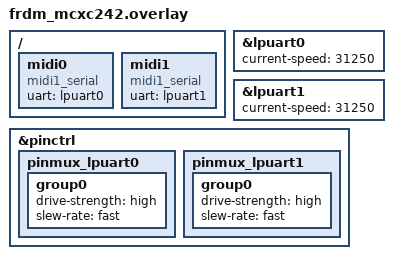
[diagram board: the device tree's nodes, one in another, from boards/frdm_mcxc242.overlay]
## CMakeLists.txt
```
# SPDX-License-Identifier: Apache-2.0

# @file CMakeLists.txt for MIDI1.0 driver app 
#
# @author Jan-Willem Smaal <usenet@gispen.org> 
# @date 20260119
cmake_minimum_required(VERSION 3.20.0)
find_package(Zephyr REQUIRED HINTS $ENV{ZEPHYR_BASE})
project(midi1_serial)

# Application logic 
FILE(GLOB app_sources src/*.c)


target_include_directories(app PRIVATE)

target_sources(app PRIVATE 
	src/main.c
)
```

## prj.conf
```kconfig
# SPDX-License-Identifier: Apache-2.0

##########################################################################
# @file prj.conf
# @brief Example MIDI1.0 Zepyr application
# @note
#
# @author Jan-Willem Smaal <usenet@gispen.org
# @date 20251220
##########################################################################
CONFIG_LOG=n
CONFIG_LOG_DEFAULT_LEVEL=0

# Let's disable the boot banner because
# on the FRDM_MCXC242 overlay we use it will go out 
# the MIDI1.0 DIN port...
CONFIG_BOOT_BANNER=y

CONFIG_MIDI1_SERIAL=y
CONFIG_MIDI1_HARMONIC=y

##########################################################################
# Tune these settings to reduce the RAM footprint
##########################################################################
CONFIG_IDLE_STACK_SIZE=128
CONFIG_ISR_STACK_SIZE=1024

# EOF
```

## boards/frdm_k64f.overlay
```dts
/*
 * SPDX-License-Identifier: Apache-2.0
 */

/**
 * @file frdm_k64f.overlay
 * @brief overlay for this (older) NXP board
 * @note
 * it is using a MIDI arduino shield but I disconnected
 * the 5V and connected it to 3.3V instead to protect the MCU inputs.
 * I should lower the output and input from 220R resistors to 33R but it
 * seems to "work" on some interfaces without that in some shape or form.
 *
 * @author Jan-Willem Smaal <usenet@gispen.org>
 * @date 20260102
 */

/*
 * Classic MIDI1.0 over DIN5 plug
 */
&uart3 {
	status = "okay";
	/* Set it to the MIDI baud rate */
	current-speed = <31250>;
};


/ {
	midi0: midi0 {
                status = "okay";
                compatible = "midi1_serial";
                uart = <&uart3>;
        };
};


/* EOF */
```

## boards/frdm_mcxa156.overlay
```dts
/*
 * SPDX-License-Identifier: Apache-2.0
 */

/**
 * @file frdm_k64f.overlay
 * @brief overlay for this board from 2024
 * @note
 *
 * Using the MCXA156 the mikroBUS socket is used for lpuart1.
 *
 * @author Jan-Willem Smaal <usenet@gispen.org>
 * @date 20260102
 */

/*
 * Classic MIDI1.0 over DIN5 plug.
 * On the MCXA156 the mikroBUS socket J1 is on LPUART1
 */
&lpuart1 {
	status = "okay";
	/* Set it to the MIDI baud rate */
	current-speed = <31250>;
};

/ {
	midi0: midi0 {
                status = "okay";
                compatible = "midi1_serial";
                uart = <&lpuart1>;
        };	
};
```

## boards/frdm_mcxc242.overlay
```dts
/*
 * SPDX-License-Identifier: Apache-2.0
 */

/*
 * @brief FRDM-MCXW242 board configuration for the MIDI1.0 demo 
 * @note
 *
 * @author Jan-Willem Smaal
 * @date 20250101
 */
 
/*
 * Classic MIDI1.0 over DIN5 plug.
 * note on the FRDM-MCXC242 the LPUART0 is shared with the MCU_LINK.
 * so be aware!   If you send printk's you need to set the baud rate
 * to 31250 from the default 115200 to see something usefull
 *
 * Also note anything you send out to the MCU_LINK will end up on the MIDI
 * port!
 *
 */
&lpuart0 {
	status = "okay";
	/* Set it to the MIDI baud rate */
	current-speed = <31250>;
};

/* This one is on the MIKRObus and is not shared with the MCU_LINK. */
&lpuart1 {
	status = "okay";
	/* Set it to the MIDI baud rate */
	current-speed = <31250>;
};

&pinctrl {
	pinmux_lpuart0: pinmux_lpuart0 {
		group0 {
			/* Strongest drive + fast edges */
			drive-strength = "high";
			slew-rate = "fast";
		};
	};
	pinmux_lpuart1: pinmux_lpuart1 {
		group0 {
			/* Strongest drive + fast edges */
			drive-strength = "high";
			slew-rate = "fast";
		};
	};
};


/ {
	midi0: midi0 {
		status = "okay";
		compatible = "midi1_serial";
		uart = <&lpuart0>;
	};
	midi1: midi1 {
		status = "okay";
		compatible = "midi1_serial";
		uart = <&lpuart1>;
	};
};
```

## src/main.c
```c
/*
 * SPDX-License-Identifier: Apache-2.0
 */

/**
 * @brief MIDI 1.0 implementation on serial UART for Zephyr
 *
 * @author Jan-Willem Smaal <usenet@gispen.org>
 * @date 20260107
 */
#include <stdio.h>
#include <zephyr/device.h>
#include <zephyr/kernel.h>
#include <zephyr/devicetree.h>
#include <zephyr/sys/printk.h>

/* Moved to ../drivers */
#include <zephyr/drivers/midi/midi1_serial.h>

/* Some helpers to print out the note name */
#include <zephyr/midi1/note.h>

/* Via Kconfig (menuconfig) the channel can be set */ 
#define MY_MIDI1_CHAN (CONFIG_MIDI1_SERIAL_CHANNEL - 1)

/**
 * @brief Callbacks/delegates for 'midi1_serial.c' after parsing MIDI1.0
 *
 * @note
 * Do not block in these function as they are called from the MIDI
 * parser this one is blocked untill the delegate is finished.
 * It's better if you have something running for a longer time
 * to fire off a workqueue. 
 */
void note_on_handler(uint8_t channel, uint8_t note, uint8_t velocity)
{
	printk("Note  on: %s %03d %03d\n", harm_note_to_text_with_octave(note, false),
	       note, velocity);
}

void note_off_handler(uint8_t channel, uint8_t note, uint8_t velocity)
{
	printk("Note off: %s %03d %03d\n", harm_note_to_text_with_octave(note, false),
	       note, velocity);
}

void pitchwheel_handler(uint8_t channel, uint8_t lsb, uint8_t msb)
{
	/* 14 bit value for the pitch wheel  */
	int16_t pwheel = (int16_t) ((msb << 7) | lsb) - PITCHWHEEL_CENTER;
	/* print on the serial out */
	printk("Pitchwheel: %d\n", pwheel);
}

void control_change_handler_model(uint8_t channel,
                                  uint8_t controller, uint8_t value)
{
	printk("CC: %d %d\n", controller, value);
}

void control_change_handler(uint8_t channel, uint8_t controller, uint8_t value)
{
	printk("CC: %d %d\n", controller, value);
}

void realtime_handler(uint8_t msg)
{
	printk("Realtime: %d\n", msg);
}

void sysex_start_handler(void)
{
	printk("sysex_start_handler()\n");
}

void sysex_data_handler(uint8_t data)
{
	printk("%x ", data);
}

void sysex_stop_handler(void)
{
	printk("\nsysex_stop_handler()\n");
}

/* ---------------------------- THREADS ------------------------------------ */

/**
 * Serial receive parser thread - receiveparser keeps reading data
 * filled by the ISR and then calls callbacks.
 */
void midi1_serial_receive_thread(void)
{
	const struct device *midi = DEVICE_DT_GET(DT_NODELABEL(midi0));

	if (!device_is_ready(midi)) {
		printk("receive_thread Serial MIDI1 device not ready\n");
		return;
	}
	const struct midi1_serial_api *mid = midi->api;

	/*
	 * Set the callbacks in the driver to our own callbacks.  Pointers
	 * left null are not used in the callbacks.
	 * e.g. right now the aftertouch is not handled.
	 */
	struct midi1_serial_callbacks my_cb = {
		.note_on = note_on_handler,
		.note_off = note_off_handler,
		.control_change = control_change_handler,
		.pitchwheel = pitchwheel_handler,
		.sysex_start = sysex_start_handler,
		.sysex_data = sysex_data_handler,
		.sysex_stop = sysex_stop_handler
	};
	/* midi1_serial_register_callbacks(midi, &my_cb); */
	mid->register_callbacks(midi, &my_cb);

	while (1) {
		/* As this call is blocking no need to sleep in between */
		mid->receiveparser(midi);
	}
}

K_THREAD_DEFINE(midi1_serial_receive_tid, 512,
                midi1_serial_receive_thread, NULL, NULL, NULL, 5, 0, 0);

/**
 * Main thread - this may actually terminate normally (code 0) in zephyr.
 * and the rest of threads keeps running just fine.
 */
int main(void)
{
	const struct device *midi = DEVICE_DT_GET(DT_NODELABEL(midi0));
	if (!device_is_ready(midi)) {
		printk("Serial MIDI1 device not ready\n");
		return 0;
	}
	/* You can either use the pointer to the API or the public interface */
	const struct midi1_serial_api *mid = midi->api;

	/* Using the API pointer */
	mid->note_on(midi, MY_MIDI1_CHAN, 1, 60);
	k_sleep(K_MSEC(290));

	/* Using the public interface for the driver same effect */
	midi1_serial_note_off(midi, MY_MIDI1_CHAN, 1, 60);
	k_sleep(K_MSEC(290));

	while (1) {
		/* Running status is used < 300 ms */
		for (uint8_t value = 0; value < 16; value++) {
			/* CC1 sweep */
			//midi1_serial_control_change(midi, CH16, 1, value);
			mid->control_change(midi, MY_MIDI1_CHAN, 1, value);
			k_sleep(K_MSEC(290));
		}
		/* Running status is not used > 300 ms */
		for (uint8_t value = 0; value < 16; value++) {
			/* note sweep */
			//midi1_serial_note_on(midi, CH7, value, 100);
			mid->note_on(midi, MY_MIDI1_CHAN, value, 100);
			k_sleep(K_MSEC(310));
		}
		/* Send as quickly as the uart poll out will allow */
		for (uint8_t value = 0; value < 16; value++) {
			/* note off sweep */
			//midi1_serial_note_off(midi, CH7, value, 100);
			mid->note_off(midi, MY_MIDI1_CHAN, value, 100);
		}
		for (uint8_t value = 0; value < 16; value++) {
			mid->start(midi);
			k_sleep(K_MSEC(100));
			mid->stop(midi);
			k_sleep(K_MSEC(100));
		}
	}
	return 0;
}

/* EOF */
```

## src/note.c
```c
/*
 * SPDX-License-Identifier: Apache-2.0
 */

/** 
 * @file note.c 
 * 
 * @brief Generic MIDI and harmony related functions 
 * implemented in support of embedded systems in c. 
 * tested on Zephyr RTOS. 
 * 
 * @author Jan-Willem Smaal <usenet@gispen.org> 
 * @updated 20241224
 */
#include "note.h"

/*
 * Return the note with the octave included.
 * not thread safe. 
 */
const char *noteToTextWithOctave(uint8_t midinote, bool flats)
{
	static char notestring[5];
	snprintf(notestring,
	         sizeof(notestring),
	         "%s%d", noteToText(midinote, flats), noteToOct(midinote));
	return &notestring[0];
}

/* This function converts a MIDI note using a lookup table to a string */
const char *noteToText(uint8_t midinote, bool flats)
{
	int octave = noteToOct(midinote);
	uint8_t note = midinote - ((octave + 2) * 12);
	static const char *flatNotes[] =
	    { "C ", "Db", "D ", "Eb", "E ", "F ", "Gb", "G ", "Ab", "A ", "Bb",
		"B "
	};
	static const char *sharpNotes[] =
	    { "C ", "C#", "D ", "D#", "E ", "F ", "F#", "G ", "G#", "A ", "A#",
		"B "
	};

	const char *noteString;
	if (flats) {
		noteString = flatNotes[note];
	} else {
		noteString = sharpNotes[note];
	}
	/*  Null-terminated string is returned from the static char array */
	return noteString;
}

/*
 * This function converts a MIDI note to an octave number 
 */
int noteToOct(uint8_t midinote)
{
	return (midinote / 12) - 2;
}

#if TODO_USING_MATH
/*
 * This function converts a MIDI note to a frequency
 * it can use a custom pitch for the A4 note.
 * TODO: implement in MCU friendly way....
 */
float noteToFreqCustomA4(uint8_t midinote, int base_a4_note_freq)
{
	return base_a4_note_freq * pow(2, (midinote - 69) / 12.0);
}
#endif

/**
 * In this case on my embedded system I don't want to run the
 * pow() match functions I use a precomputed lookup table.
 * A=440Hz is a given then.
 * TODO: possibly create multiple tables with some
 * TODO: variation in pitch of A4.  Flash size tradeoff.   
 */
#include "midi_freq_table.h"
float noteToFreq(uint8_t midinote)
{
	return midi_freq_table[midinote];
}

#if TODO_USING_MATH
uint8_t freqToMidiNote(float freq)
{
	/* Fast inverse using log2f */
	float n = 69.0f + 12.0f * log2f(freq / BASE_A4_NOTE_FREQ);
	if (n < 0)
		n = 0;
	if (n > 127)
		n = 127;
	return (uint8_t) (n + 0.5f);
}
#endif

/**
 * @brief Convert a frequency value to the nearest MIDI note number.
 *
 * This function uses a binary search over the precomputed MIDI note
 * frequency table (0–127).
 *
 * @param freq  Input frequency in Hz
 * @return      MIDI note number (0–127) that best matches the frequency
 *
 * TODO update for MIDI 2.0 to include per note offsets.
 */
uint8_t freqToMidiNote(float freq)
{
	int min = 0;
	int max = 127;

	while (min <= max) {
		int mid = (min + max) / 2;

		if (freq > midi_freq_table[mid]) {
			min = mid + 1;
		} else if (freq < midi_freq_table[mid]) {
			max = mid - 1;
		} else {
			/* exact match */
			return mid;
		}
	}

	/*  min is now the first note with freq_table[min] > freq */
	if (min == 0) {
		return 0;
	}
	if (min > 127) {
		return 127;
	}

	/* pick closest of min and min-1 */
	float low = midi_freq_table[min - 1];
	float high = midi_freq_table[min];

	return (freq - low < high - freq) ? (min - 1) : min;
}

/* EOF */
```
